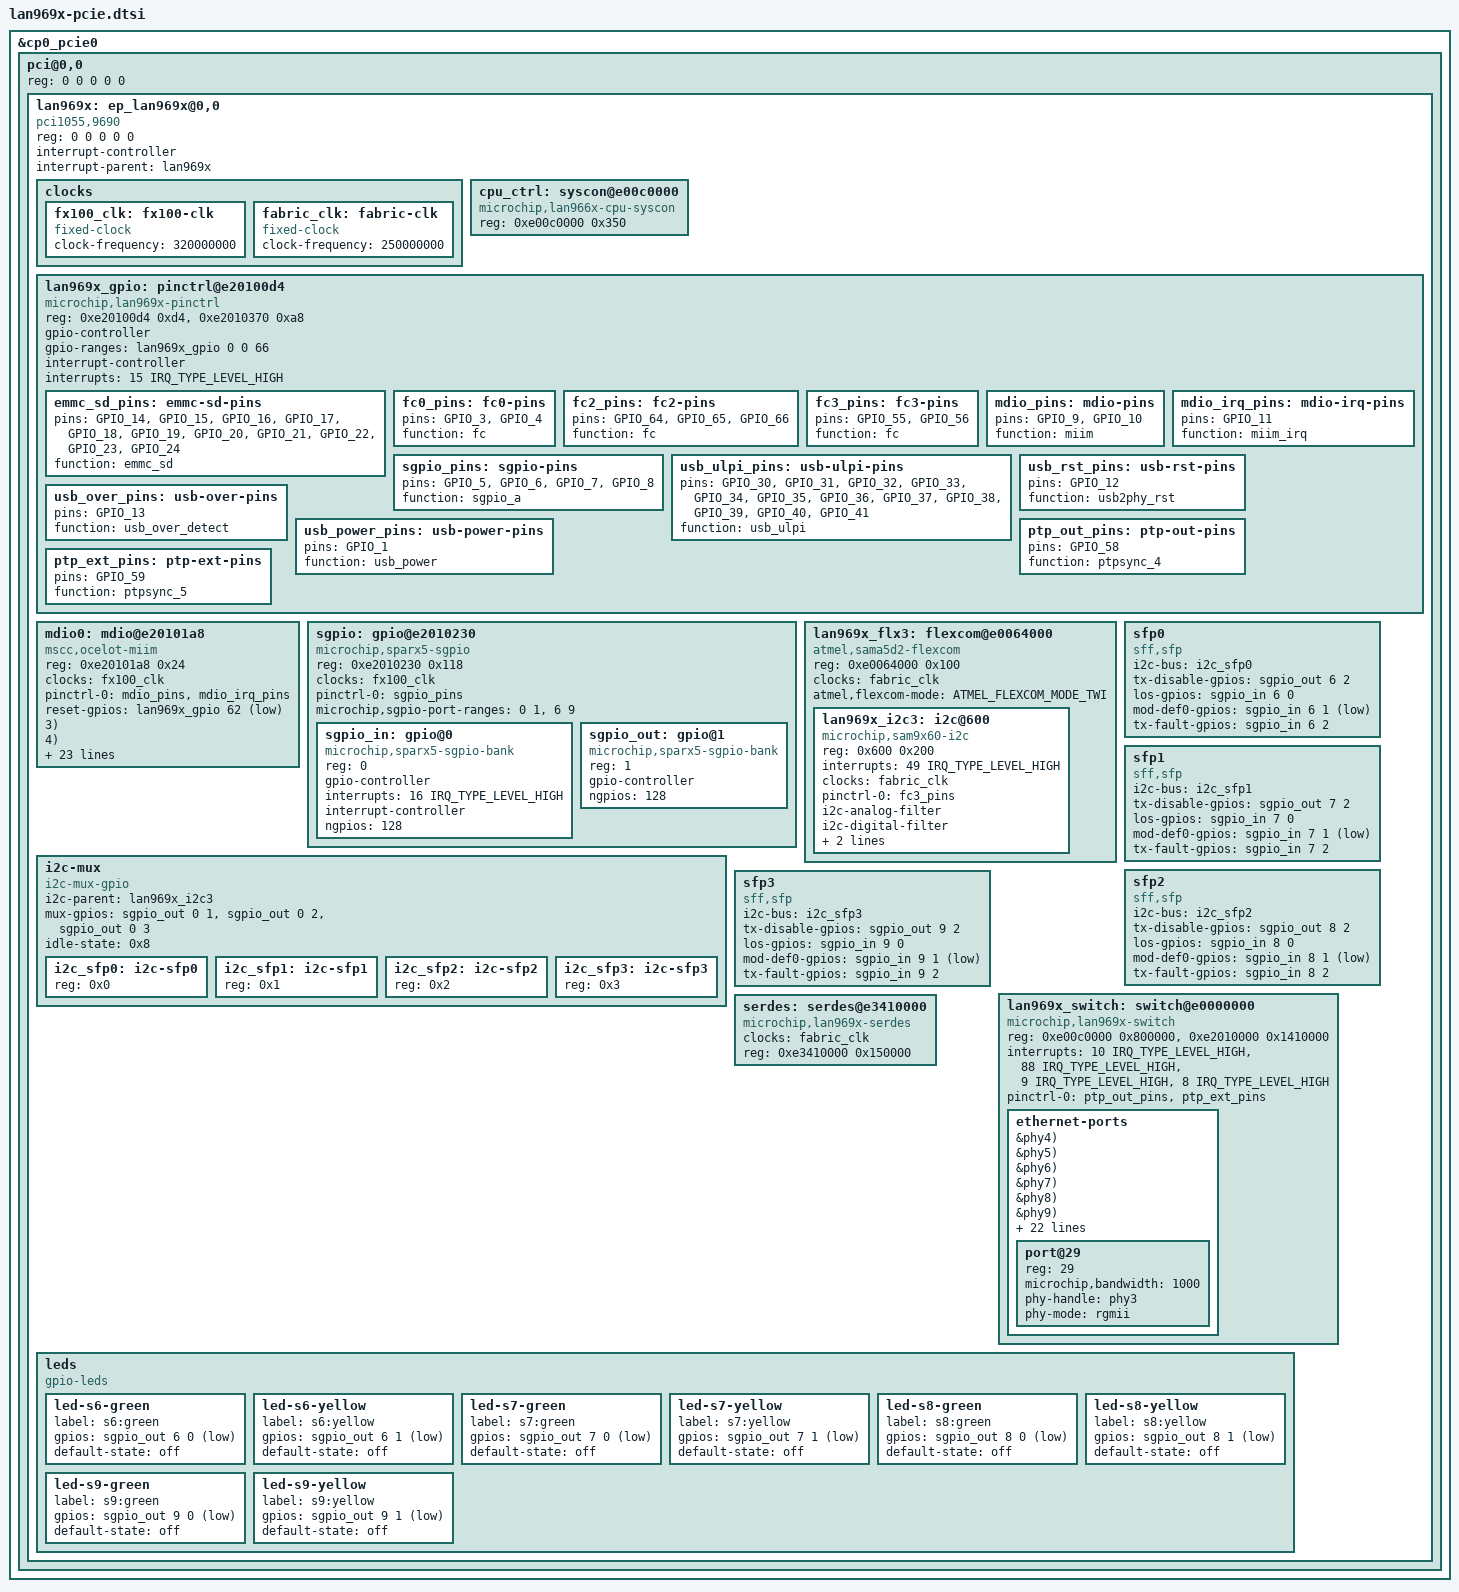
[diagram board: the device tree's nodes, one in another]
// SPDX-License-Identifier: GPL-2.0

#include <dt-bindings/mfd/atmel-flexcom.h>
#include <dt-bindings/clock/microchip,lan966x.h>

&cp0_pcie0 {
	pci@0,0 {
		#address-cells = <3>;
		#size-cells = <2>;
		device_type = "pci";

		reg = <0 0 0 0 0>;
		ranges = <0x02000000 0x0 0xc0000000 0x02000000 0x0 0xc0000000 0x0 0x40000000>;

		lan969x: ep_lan969x@0,0 {
			compatible = "pci1055,9690";

			reg = <0 0 0 0 0>;
			#address-cells = <1>;
			#size-cells = <1>;

			ranges = <0xe2000000 0x02000000 0x0 0xc0000000 0x02000000>,
			         <0xe0000000 0x02000000 0x0 0xc2000000 0x01000000>;

			#interrupt-cells = <2>;
			interrupt-controller;
			interrupt-parent = <&lan969x>;

			clocks {
				fx100_clk: fx100-clk {
					compatible = "fixed-clock";
					#clock-cells = <0>;
					clock-frequency = <320000000>;
				};

				fabric_clk: fabric-clk {
					compatible = "fixed-clock";
					#clock-cells = <0>;
					clock-frequency = <250000000>;
				};
			};

			cpu_ctrl: syscon@e00c0000 {
				compatible = "microchip,lan966x-cpu-syscon", "syscon";
				reg = <0xe00c0000 0x350>;
			};

			lan969x_gpio: pinctrl@e20100d4 {
				compatible = "microchip,lan969x-pinctrl";
				reg = <0xe20100d4 0xd4>,
				      <0xe2010370 0xa8>;
				gpio-controller;
				#gpio-cells = <2>;
				gpio-ranges = <&lan969x_gpio 0 0 66>;
				interrupt-controller;
				interrupts = <15 IRQ_TYPE_LEVEL_HIGH>;
				#interrupt-cells = <2>;
				#address-cells = <1>;
			};

			mdio0: mdio@e20101a8 {
				compatible = "mscc,ocelot-miim";
				#address-cells = <1>;
				#size-cells = <0>;
				reg = <0xe20101a8 0x24>;
				clocks = <&fx100_clk>;
				status = "disabled";
			};

			sgpio: gpio@e2010230 {
				compatible = "microchip,sparx5-sgpio";
				reg = <0xe2010230 0x118>;
				clocks = <&fx100_clk>;
				#address-cells = <1>;
				#size-cells = <0>;
				status = "disabled";

				sgpio_in: gpio@0 {
					compatible = "microchip,sparx5-sgpio-bank";
					reg = <0>;
					gpio-controller;
					#gpio-cells = <3>;
					interrupts = <16 IRQ_TYPE_LEVEL_HIGH>;
					interrupt-controller;
					#interrupt-cells = <3>;
					#adress-cells = <0>;
				};

				sgpio_out: gpio@1 {
					compatible = "microchip,sparx5-sgpio-bank";
					reg = <1>;
					gpio-controller;
					#gpio-cells = <3>;
				};
			};

			lan969x_flx3: flexcom@e0064000 {
				compatible = "atmel,sama5d2-flexcom";
				reg = <0xe0064000 0x100>;
				clocks = <&fabric_clk>;
				#address-cells = <1>;
				#size-cells = <1>;
				ranges = <0x0 0xe0064000 0x800>;

				atmel,flexcom-mode = <ATMEL_FLEXCOM_MODE_TWI>;
				status = "okay";

				lan969x_i2c3: i2c@600 {
					compatible = "microchip,sam9x60-i2c";
					reg = <0x600 0x200>;
					interrupts = <49 IRQ_TYPE_LEVEL_HIGH>;
					clocks = <&fabric_clk>;
					#address-cells = <1>;
					#size-cells = <0>;
					pinctrl-0 = <&fc3_pins>;
					pinctrl-names = "default";
					i2c-analog-filter;
					i2c-digital-filter;
					i2c-digital-filter-width-ns = <35>;
					i2c-sda-hold-time-ns = <1500>;
					status = "okay";
				};
			};

			i2c-mux {
				compatible = "i2c-mux-gpio";
				#address-cells = <1>;
				#size-cells = <0>;
				i2c-parent = <&lan969x_i2c3>;

				mux-gpios = <&sgpio_out 0 1 GPIO_ACTIVE_HIGH
					     &sgpio_out 0 2 GPIO_ACTIVE_HIGH
					     &sgpio_out 0 3 GPIO_ACTIVE_HIGH>;
				idle-state = <0x8>;

				i2c_sfp0: i2c-sfp0 {
					reg = <0x0>;
				};

				i2c_sfp1: i2c-sfp1 {
					reg = <0x1>;
				};

				i2c_sfp2: i2c-sfp2 {
					reg = <0x2>;
				};

				i2c_sfp3: i2c-sfp3 {
					reg = <0x3>;
				};
			};

			sfp0: sfp0 {
				compatible = "sff,sfp";
				i2c-bus = <&i2c_sfp0>;
				tx-disable-gpios = <&sgpio_out 6 2 GPIO_ACTIVE_HIGH>;
				los-gpios = <&sgpio_in 6 0 GPIO_ACTIVE_HIGH>;
				mod-def0-gpios = <&sgpio_in 6 1 GPIO_ACTIVE_LOW>;
				tx-fault-gpios = <&sgpio_in 6 2 GPIO_ACTIVE_HIGH>;
			};

			sfp1: sfp1 {
				compatible = "sff,sfp";
				i2c-bus = <&i2c_sfp1>;
				tx-disable-gpios = <&sgpio_out 7 2 GPIO_ACTIVE_HIGH>;
				los-gpios = <&sgpio_in 7 0 GPIO_ACTIVE_HIGH>;
				mod-def0-gpios = <&sgpio_in 7 1 GPIO_ACTIVE_LOW>;
				tx-fault-gpios = <&sgpio_in 7 2 GPIO_ACTIVE_HIGH>;
			};

			sfp2: sfp2 {
				compatible = "sff,sfp";
				i2c-bus = <&i2c_sfp2>;
				tx-disable-gpios = <&sgpio_out 8 2 GPIO_ACTIVE_HIGH>;
				los-gpios = <&sgpio_in 8 0 GPIO_ACTIVE_HIGH>;
				mod-def0-gpios = <&sgpio_in 8 1 GPIO_ACTIVE_LOW>;
				tx-fault-gpios = <&sgpio_in 8 2 GPIO_ACTIVE_HIGH>;
			};

			sfp3: sfp3 {
				compatible = "sff,sfp";
				i2c-bus = <&i2c_sfp3>;
				tx-disable-gpios = <&sgpio_out 9 2 GPIO_ACTIVE_HIGH>;
				los-gpios = <&sgpio_in 9 0 GPIO_ACTIVE_HIGH>;
				mod-def0-gpios = <&sgpio_in 9 1 GPIO_ACTIVE_LOW>;
				tx-fault-gpios = <&sgpio_in 9 2 GPIO_ACTIVE_HIGH>;
			};

			lan969x_switch: switch@e0000000 {
				compatible = "microchip,lan969x-switch";
				reg = <0xe00c0000 0x800000>,
				      <0xe2010000 0x1410000>;
				reg-names = "cpu", "dev";
				interrupt-names = "xtr", "fdma", "ptp", "ptp-ext";
				interrupts = <10 IRQ_TYPE_LEVEL_HIGH>,
					     <88 IRQ_TYPE_LEVEL_HIGH>,
					     <9 IRQ_TYPE_LEVEL_HIGH>,
					     <8 IRQ_TYPE_LEVEL_HIGH>;
			};

			serdes: serdes@e3410000 {
				compatible = "microchip,lan969x-serdes";
				#phy-cells = <1>;
				clocks = <&fabric_clk>;
				reg = <0xe3410000 0x150000>;
			};

			leds {
				compatible = "gpio-leds";

				led-s6-green {
					label = "s6:green";
					gpios = <&sgpio_out 6 0 GPIO_ACTIVE_LOW>;
					default-state = "off";
				};

				led-s6-yellow {
					label = "s6:yellow";
					gpios = <&sgpio_out 6 1 GPIO_ACTIVE_LOW>;
					default-state = "off";
				};

				led-s7-green {
					label = "s7:green";
					gpios = <&sgpio_out 7 0 GPIO_ACTIVE_LOW>;
					default-state = "off";
				};

				led-s7-yellow {
					label = "s7:yellow";
					gpios = <&sgpio_out 7 1 GPIO_ACTIVE_LOW>;
					default-state = "off";
				};

				led-s8-green {
					label = "s8:green";
					gpios = <&sgpio_out 8 0 GPIO_ACTIVE_LOW>;
					default-state = "off";
				};

				led-s8-yellow {
					label = "s8:yellow";
					gpios = <&sgpio_out 8 1 GPIO_ACTIVE_LOW>;
					default-state = "off";
				};

				led-s9-green {
					label = "s9:green";
					gpios = <&sgpio_out 9 0 GPIO_ACTIVE_LOW>;
					default-state = "off";
				};

				led-s9-yellow {
					label = "s9:yellow";
					gpios = <&sgpio_out 9 1 GPIO_ACTIVE_LOW>;
					default-state = "off";
				};
			};
		};
	};
};

&lan969x_gpio {
	emmc_sd_pins: emmc-sd-pins {
		/* eMMC_SD - CMD, CLK, D0, D1, D2, D3, D4, D5, D6, D7, RSTN */
		pins = "GPIO_14", "GPIO_15", "GPIO_16", "GPIO_17",
		       "GPIO_18", "GPIO_19", "GPIO_20", "GPIO_21",
		       "GPIO_22", "GPIO_23", "GPIO_24";
		function = "emmc_sd";
	};

	fc0_pins: fc0-pins {
		pins = "GPIO_3", "GPIO_4";
		function = "fc";
	};

	fc2_pins: fc2-pins {
		pins = "GPIO_64", "GPIO_65", "GPIO_66";
		function = "fc";
	};

	fc3_pins: fc3-pins {
		pins = "GPIO_55", "GPIO_56";
		function = "fc";
	};

	mdio_pins: mdio-pins {
		pins = "GPIO_9", "GPIO_10";
		function = "miim";
	};

	mdio_irq_pins: mdio-irq-pins {
		pins = "GPIO_11";
		function = "miim_irq";
	};

	sgpio_pins: sgpio-pins {
		/* SCK, D0, D1, LD */
		pins = "GPIO_5", "GPIO_6", "GPIO_7", "GPIO_8";
		function = "sgpio_a";
	};

	usb_ulpi_pins: usb-ulpi-pins {
		pins = "GPIO_30", "GPIO_31", "GPIO_32", "GPIO_33",
		"GPIO_34", "GPIO_35", "GPIO_36", "GPIO_37",
		"GPIO_38", "GPIO_39", "GPIO_40", "GPIO_41";
		function = "usb_ulpi";
	};

	usb_rst_pins: usb-rst-pins {
		pins = "GPIO_12";
		function = "usb2phy_rst";
	};

	usb_over_pins: usb-over-pins {
		pins = "GPIO_13";
		function = "usb_over_detect";
	};

	usb_power_pins: usb-power-pins {
		pins = "GPIO_1";
		function = "usb_power";
	};

	ptp_out_pins: ptp-out-pins {
		pins = "GPIO_58";
		function = "ptpsync_4";
	};

	ptp_ext_pins: ptp-ext-pins {
		pins = "GPIO_59";
		function = "ptpsync_5";
	};
};

&mdio0 {
	pinctrl-0 = <&mdio_pins>, <&mdio_irq_pins>;
	pinctrl-names = "default";
	reset-gpios = <&lan969x_gpio 62 GPIO_ACTIVE_LOW>;
	status = "okay";

#define CU_PHY(_reg) \
	phy@_reg { \
		reg = <_reg>; \
		interrupts = <11 IRQ_TYPE_LEVEL_LOW>; \
		interrupt-parent = <&lan969x_gpio>; \
	}

	phy3:  CU_PHY( 3);

	phy4:  CU_PHY( 4); phy5:  CU_PHY( 5); phy6:  CU_PHY( 6); phy7:  CU_PHY( 7);
	phy8:  CU_PHY( 8); phy9:  CU_PHY( 9); phy10: CU_PHY(10); phy11: CU_PHY(11);
	phy12: CU_PHY(12); phy13: CU_PHY(13); phy14: CU_PHY(14); phy15: CU_PHY(15);

	phy16: CU_PHY(16); phy17: CU_PHY(17); phy18: CU_PHY(18); phy19: CU_PHY(19);
	phy20: CU_PHY(20); phy21: CU_PHY(21); phy22: CU_PHY(22); phy23: CU_PHY(23);
	phy24: CU_PHY(24); phy25: CU_PHY(25); phy26: CU_PHY(26); phy27: CU_PHY(27);
};

&sgpio {
	pinctrl-0 = <&sgpio_pins>;
	pinctrl-names = "default";

	microchip,sgpio-port-ranges = <0 1>, <6 9>;
	status = "okay";

	gpio@0 {
		ngpios = <128>;
	};
	gpio@1 {
		ngpios = <128>;
	};
};

&serdes {
	status = "okay";
};

&lan969x_switch {
	pinctrl-0 = <&ptp_out_pins>, <&ptp_ext_pins>;
	pinctrl-names = "default";

	status = "okay";
	ethernet-ports {
		#address-cells = <1>;
		#size-cells = <0>;

#define CU_SWP(_reg, _phy) \
		port@_reg { \
			reg = <_reg>; \
			microchip,bandwidth = <1000>; \
			phy-handle = <_phy>; \
			phy-mode = "qsgmii"; \
			phys = <&serdes (_reg / 4)>; \
		}

		CU_SWP( 0,  &phy4); CU_SWP( 1,  &phy5); CU_SWP( 2,  &phy6); CU_SWP( 3,  &phy7);
		CU_SWP( 4,  &phy8); CU_SWP( 5,  &phy9); CU_SWP( 6, &phy10); CU_SWP( 7, &phy11);
		CU_SWP( 8, &phy12); CU_SWP( 9, &phy13); CU_SWP(10, &phy14); CU_SWP(11, &phy15);

		CU_SWP(12, &phy16); CU_SWP(13, &phy17); CU_SWP(14, &phy18); CU_SWP(15, &phy19);
		CU_SWP(16, &phy20); CU_SWP(17, &phy21); CU_SWP(18, &phy22); CU_SWP(19, &phy23);
		CU_SWP(20, &phy24); CU_SWP(21, &phy25); CU_SWP(22, &phy26); CU_SWP(23, &phy27);

#define SERDES_SWP(_reg, _lane, _sfp, _gpio) \
		port@_reg { \
			reg = <_reg>; \
			microchip,bandwidth = <10000>; \
			phys = <&serdes _lane>; \
			phy-mode = "10gbase-r"; \
			sfp = <_sfp>; \
			microchip,sd-sgpio = <_gpio>; \
			managed = "in-band-status"; \
		}

		SERDES_SWP(24, 6, &sfp0, 365);
		SERDES_SWP(25, 7, &sfp1, 369);
		SERDES_SWP(26, 8, &sfp2, 373);
		SERDES_SWP(27, 9, &sfp3, 377);

		port@29 {
			reg = <29>;
			microchip,bandwidth = <1000>;
			phy-handle = <&phy3>;
			phy-mode = "rgmii";
		};
	};
};
